AUTOSAR XML (schema 4-2-1)
standard types defined: float32, float64, sint8, sint16, sint32, uint8, uint16, uint32, boolean, dtRef_VOID, Float32, Boolean, UInt16, UInt8, UInt32
package /FoundationPkg/FoundationArchitecturePkg
  client server interface iRack
    8 x operation:
      getMaxPhysicalAssist
        arg maxPhysicalAssist: type=Nm, direction=OUT
      initialisationColumnAngle
        arg pinionAngle: type=Degrees, direction=IN
      translateColumnAngleToRackPosition
        arg pinionAngle: type=Degrees, direction=IN
        arg rackPosition: type=mm, direction=OUT
      translateColumnTorqueToRackForce
        arg columnTorque: type=Nm, direction=IN
        arg rackForce: type=kN, direction=OUT
      translateRackPositionToColumnAngle
        arg rackPosition: type=mm, direction=IN
        arg columnAngle: type=Degrees, direction=OUT
      translateRackForceToColumnTorque
        arg rackForce: type=kN, direction=IN
        arg columnTorque: type=Nm, direction=OUT
      translateColumnVelocityToRackVelocity
        arg columnVelocity: type=DegreesPerSec, direction=IN
        arg rackVelocity: type=mmPerSec, direction=OUT
      translateRackVelocityToColumnVelocity
        arg rackVelocity: type=mmPerSec, direction=IN
        arg columnVelocity: type=DegreesPerSec, direction=OUT
  constant specification iAssistTorque_AssistanceTorque_Init: value-spec={short-label=iAssistTorque_AssistanceTorque_Init, fields=[0 Nm_Unit, 0]}
  sender receiver interface iAssistTorque
    data AssistanceTorque: sw-calibration-access=READ-ONLY, type=tAssistTorque, init-value=constant-reference=iAssistTorque_AssistanceTorque_Init
  constant specification iArbitatorRequest_ActivationRequest_Init: value-spec=0
  sender receiver interface iArbitatorRequest
    data ActivationRequest: sw-calibration-access=READ-ONLY, type=tArbitrationState, init-value=constant-reference=iArbitatorRequest_ActivationRequest_Init
  constant specification iArbitorResponse_ArbitrationState_Init: value-spec=5
  sender receiver interface iArbitorResponse
    data ArbitrationState: sw-calibration-access=READ-ONLY, type=tArbitrationState, init-value=constant-reference=iArbitorResponse_ArbitrationState_Init
  constant specification iInputTorqueDemands_OverlayTorqueDemand_Init: value-spec={short-label=iInputTorqueDemands_OverlayTorqueDemand_Init, fields=[0 Nm_Unit, 0 NmPerSec_Unit, 0]}
  constant specification iInputTorqueDemands_LimitingTorqueDemand_Init: value-spec={short-label=iInputTorqueDemands_LimitingTorqueDemand_Init, fields=[0 Nm_Unit, 0]}
  sender receiver interface iInputTorqueDemands
    data OverlayTorqueDemand: sw-calibration-access=READ-ONLY, type=tInputTorque, init-value=constant-reference=iInputTorqueDemands_OverlayTorqueDemand_Init
    data LimitingTorqueDemand: sw-calibration-access=READ-ONLY, type=tAssistTorque, init-value=constant-reference=iInputTorqueDemands_LimitingTorqueDemand_Init
  constant specification iVehicleData_VehicleSpeed_Init: value-spec={short-label=iVehicleData_VehicleSpeed_Init, fields=[0 Kph_Unit, 0, 0]}
  constant specification iVehicleData_SteeringAngle_Init: value-spec={short-label=iVehicleData_SteeringAngle_Init, fields=[0 Degrees_Unit, 0]}
  sender receiver interface iVehicleData
    data VehicleSpeed: sw-calibration-access=READ-ONLY, type=tVehicleSpd, init-value=constant-reference=iVehicleData_VehicleSpeed_Init
    data SteeringAngle: sw-calibration-access=READ-ONLY, type=tColumnPosition, init-value=constant-reference=iVehicleData_SteeringAngle_Init
  5 x constant specification:
    iColumnData_ColumnTorque_Init: value-spec={short-label=iColumnData_ColumnTorque_Init, fields=[0 Nm_Unit, 0 NmPerSec_Unit, 0]}
    iColumnData_SteeringPositionLower_Init: value-spec={short-label=iColumnData_SteeringPositionLower_Init, fields=[0 Degrees_Unit, 0]}
    iColumnData_ColumnVelocity_Init: value-spec={short-label=iColumnData_ColumnVelocity_Init, fields=[0 RevsPerSec_Unit, 0 RevsPerSec_Unit, 0]}
    iColumnData_SteeringPositionUpper_Init: value-spec={short-label=iColumnData_SteeringPositionUpper_Init, fields=[0 Degrees_Unit, 0]}
    iColumnData_ColumnPositionLower_Init: value-spec={short-label=iColumnData_ColumnPositionLower_Init, fields=[0 Degrees_Unit, 0]}
  sender receiver interface iColumnData
    5 x data, all with sw-calibration-access=READ-ONLY:
      ColumnTorque: type=tInputTorque, init-value=constant-reference=iColumnData_ColumnTorque_Init
      SteeringPositionLower: type=tColumnPosition, init-value=constant-reference=iColumnData_SteeringPositionLower_Init
      ColumnVelocity: type=tColumnVelocity, init-value=constant-reference=iColumnData_ColumnVelocity_Init
      SteeringPositionUpper: type=tColumnPosition, init-value=constant-reference=iColumnData_SteeringPositionUpper_Init
      ColumnPositionLower: type=tMechanicalMotorPosition, init-value=constant-reference=iColumnData_ColumnPositionLower_Init
  constant specification iAssistCapability_Capability_Init: value-spec={short-label=iAssistCapability_Capability_Init, fields=[0 Percent_Unit, 0 Percent_Unit]}
  sender receiver interface iAssistCapability
    data Capability: sw-calibration-access=READ-ONLY, type=tAssistCapability, init-value=constant-reference=iAssistCapability_Capability_Init
package /FoundationPkg/FoundationArchitecturePkg/FoundationTypes
  unit Nm_Unit
  impl type Nm: implementation-data-type=Float32
  unit Degrees_Unit
  impl type Degrees: implementation-data-type=Float32
  unit mm_Unit
  impl type mm: implementation-data-type=Float32
  unit kN_Unit
  impl type kN: implementation-data-type=Float32
  unit DegreesPerSec_Unit
  impl type DegreesPerSec: implementation-data-type=Float32
  unit mmPerSec_Unit
  impl type mmPerSec: implementation-data-type=Float32
  compu method tQualityFactor_Compu: 0=QF_UNINITIALIZED, 0=QF_UNINITIALISED, 1=QF_UNAVAILABLE, 2=QF_DEGRADED, 3=QF_FULL
  impl type tQualityFactor: category=VALUE, base-type=sint32, compu-method=tQualityFactor_Compu
  impl type tAssistTorque: category=STRUCTURE
    element Value: implementation-data-type=Nm
    element Qf: implementation-data-type=tQualityFactor
  compu method tArbitrationState_Compu: 0=ARB_PASSIVE, 1=ARB_REQ_ACT, 2=ARB_RAMP_IN, 3=ARB_ACTIVE, 4=ARB_RAMP_OUT, 5=ARB_LOCKED, 99=ARB_READY
  impl type tArbitrationState: category=VALUE, base-type=sint32, compu-method=tArbitrationState_Compu
  unit NmPerSec_Unit
  impl type NmPerSec: implementation-data-type=Float32
  impl type tInputTorque: category=STRUCTURE
    element Value: implementation-data-type=Nm
    element Derivative: implementation-data-type=NmPerSec
    element Qf: implementation-data-type=tQualityFactor
  unit Kph_Unit
  impl type Kph: implementation-data-type=Float32
  impl type tVehicleSpd: category=STRUCTURE
    element Filtered: implementation-data-type=Kph
    element Moving: implementation-data-type=Boolean
    element Qf: implementation-data-type=tQualityFactor
  impl type tColumnPosition: category=STRUCTURE
    element Value: implementation-data-type=Degrees
    element Qf: implementation-data-type=tQualityFactor
  unit RevsPerSec_Unit
  impl type RevsPerSec: implementation-data-type=Float32
  impl type tColumnVelocity: category=STRUCTURE
    element Filtered: implementation-data-type=RevsPerSec
    element Unfiltered: implementation-data-type=RevsPerSec
    element Qf: implementation-data-type=tQualityFactor
  impl type tMechanicalMotorPosition: category=STRUCTURE
    element Value: implementation-data-type=Degrees
    element Qf: implementation-data-type=tQualityFactor
  unit Percent_Unit
  impl type Percent: implementation-data-type=Float32
  impl type tAssistCapability: category=STRUCTURE
    element Limit: implementation-data-type=Percent
    element Scale: implementation-data-type=Percent
  8 x constant specification:
    ActiveReturnTqDemand_Value_Init: value-spec=0.0
    ActiveReturnTqDemand_Qf_Init: value-spec=0
    DampingTqDemand_Value_Init: value-spec=0.0
    DampingTqDemand_Qf_Init: value-spec=0
    HvdTqDemand_Value_Init: value-spec=0.0
    HvdTqDemand_Qf_Init: value-spec=0
    ResTqDemand_Value_Init: value-spec=0.0
    ResTqDemand_Qf_Init: value-spec=0
  10 x constant specification:
    StdrTqDemand_Value_Init: value-spec=0.0
    StdrTqDemand_Qf_Init: value-spec=0
    PaTqDemand_Value_Init: value-spec=0.0
    PaTqDemand_Qf_Init: value-spec=0
    SrlTqDemand_Value_Init: value-spec=0.0
    SrlTqDemand_Qf_Init: value-spec=0
    AncTqDemand_Value_Init: value-spec=0.0
    AncTqDemand_Qf_Init: value-spec=0
    PdcTqDemand_Value_Init: value-spec=0.0
    PdcTqDemand_Qf_Init: value-spec=0
  unit Sec_Unit
  impl type Sec: implementation-data-type=Float32
  unit Hz_Unit
  impl type Hz: implementation-data-type=Float32
  unit ms_Unit
  impl type ms: implementation-data-type=UInt32
package /FoundationPkg/FoundationArchitecturePkg/FoundationTypes/ApplicationTypesPkg
  9 x app type, all with category=VALUE:
    Nm: compu {identical; unit Nm_Unit}, range phys -10..10, unit=Nm_Unit
    Float32: compu {identical}
    Degrees: compu {identical; unit Degrees_Unit}, unit=Degrees_Unit
    mm: compu {identical; unit mm_Unit}, unit=mm_Unit
    kN: compu {identical; unit kN_Unit}, unit=kN_Unit
    DegreesPerSec: compu {identical; unit DegreesPerSec_Unit}, unit=DegreesPerSec_Unit
    mmPerSec: compu {identical; unit mmPerSec_Unit}, unit=mmPerSec_Unit
    Nm_n255_0_to_255_0: compu {identical; unit Nm_Unit}, range phys -255..255, unit=Nm_Unit
    tQualityFactor: base-type=sint32, compu-method=tQualityFactor_Compu
  application record data type tAssistTorque: category=STRUCTURE
    application record element Value: category=VALUE, type=Nm_n255_0_to_255_0
    application record element Qf: category=VALUE, type=tQualityFactor
  app type tArbitrationState: category=VALUE, base-type=sint32, compu-method=tArbitrationState_Compu
  app type NmPerSec: category=VALUE, compu {identical; unit NmPerSec_Unit}, range phys -2048..2048, unit=NmPerSec_Unit  # Rate of change of torque
  application record data type tInputTorque: category=STRUCTURE
    application record element Value: category=VALUE, type=Nm
    application record element Derivative: category=VALUE, type=NmPerSec
    application record element Qf: category=VALUE, type=tQualityFactor
  app type Kph_0_to_400: category=VALUE, compu {identical; unit Kph_Unit}, range phys 0..400, unit=Kph_Unit
  app type Boolean: category=VALUE
  application record data type tVehicleSpd: category=STRUCTURE
    application record element Filtered: category=VALUE, type=Kph_0_to_400
    application record element Moving: category=VALUE, type=Boolean
    application record element Qf: category=VALUE, type=tQualityFactor
  app type Kph: category=VALUE, compu {identical; unit Kph_Unit}, unit=Kph_Unit
  app type Degrees_n720_0_to_720_0: category=VALUE, compu {identical; unit Degrees_Unit}, range phys -720..720, unit=Degrees_Unit
  application record data type tColumnPosition: category=STRUCTURE  # Measument of the Column position in degrees with range -720 - +720.
    application record element Value: category=VALUE, type=Degrees_n720_0_to_720_0
    application record element Qf: category=VALUE, type=tQualityFactor
  app type RevsPerSec: category=VALUE, compu {identical; unit RevsPerSec_Unit}, unit=RevsPerSec_Unit
  application record data type tColumnVelocity: category=STRUCTURE
    application record element Filtered: category=VALUE, type=RevsPerSec
    application record element Unfiltered: category=VALUE, type=RevsPerSec
    application record element Qf: category=VALUE, type=tQualityFactor
  app type Degrees_n29520_to_29520: category=VALUE, compu {identical; unit Degrees_Unit}, range phys -29520..29520, unit=Degrees_Unit
  application record data type tMechanicalMotorPosition: category=STRUCTURE
    application record element Value: category=VALUE, type=Degrees_n29520_to_29520
    application record element Qf: category=VALUE, type=tQualityFactor
  app type Percent: category=VALUE, compu {identical; unit Percent_Unit}, range phys 0..100, unit=Percent_Unit
  application record data type tAssistCapability: category=STRUCTURE
    application record element Limit: category=VALUE, type=Percent
    application record element Scale: category=VALUE, type=Percent
  26 x app type, all with category=VALUE:
    UInt16: compu {identical}
    Float32_0_0_to_1_0: compu {identical}, range phys 0..1
    UInt8_0_to_7: compu {identical}, range phys 0..7
    Float32_0_to_1: compu {identical}, range phys 0..1
    UInt32_0_to_3: compu {identical}, range phys 0..3
    Sec_0_1_to_1: compu {identical; unit Sec_Unit}, range phys 0.1..1, unit=Sec_Unit
    Sec_0_1_to_0_5: compu {identical; unit Sec_Unit}, range phys 0.1..0.5, unit=Sec_Unit
    Boolean_0_to_1
    Hz_10_0_to_250_0: compu {identical; unit Hz_Unit}, range phys 10..250, unit=Hz_Unit
    Kph_0_0_to_300_0: compu {identical; unit Kph_Unit}, range phys 0..300, unit=Kph_Unit
    Nm_n8_0_to_8_0: compu {identical; unit Nm_Unit}, range phys -8..8, unit=Nm_Unit
    Float32_0_0_to_200_0: compu {identical}, range phys 0..200
    NmPerSec_0_to_100: compu {identical; unit NmPerSec_Unit}, range phys 0..100, unit=NmPerSec_Unit  # Rate of change of torque
    DegreesPerSec_0_to_1000: compu {identical; unit DegreesPerSec_Unit}, range phys 0..1000, unit=DegreesPerSec_Unit
    NmPerSec_0_to_1000: compu {identical; unit NmPerSec_Unit}, range phys 0..1000, unit=NmPerSec_Unit  # Rate of change of torque
    DegreesPerSec_n500_0_to_500_0: compu {identical; unit DegreesPerSec_Unit}, range phys -500..500, unit=DegreesPerSec_Unit
    Nm_0_to_200: compu {identical; unit Nm_Unit}, range phys 0..200, unit=Nm_Unit
    Kph_0_0_to_400_0: compu {identical; unit Kph_Unit}, range phys 0..400, unit=Kph_Unit
    Nm_0_0_to_20_0: compu {identical; unit Nm_Unit}, range phys 0..20, unit=Nm_Unit
    Nm_0_0_to_60_0: compu {identical; unit Nm_Unit}, range phys 0..60, unit=Nm_Unit
    ms_0_to_500: compu {identical; unit ms_Unit}, range phys 0..500, unit=ms_Unit
    UInt32: compu {identical}
    Nm_0_0_to_10_0: compu {identical; unit Nm_Unit}, range phys 0..10, unit=Nm_Unit
    Percent_0_0_to_100_0: compu {identical; unit Percent_Unit}, range phys 0..100, unit=Percent_Unit
    Nm_0_0_to_200_0: compu {identical; unit Nm_Unit}, range phys 0..200, unit=Nm_Unit
    NmPerSec_0_1_to_20_0: compu {identical; unit NmPerSec_Unit}, range phys 0.1..20, unit=NmPerSec_Unit  # Rate of change of torque
package /DataTypeMappingSets
  data type mapping set MappingSet
    data-type-maps:
      application-data-type=Float32, implementation-data-type=Float32
      application-data-type=Nm, implementation-data-type=Nm
      application-data-type=Degrees, implementation-data-type=Degrees
      application-data-type=mm, implementation-data-type=mm
      application-data-type=kN, implementation-data-type=kN
      application-data-type=DegreesPerSec, implementation-data-type=DegreesPerSec
      application-data-type=mmPerSec, implementation-data-type=mmPerSec
      application-data-type=Nm_n255_0_to_255_0, implementation-data-type=Nm
      application-data-type=tQualityFactor, implementation-data-type=tQualityFactor
      application-data-type=tAssistTorque, implementation-data-type=tAssistTorque
      application-data-type=tArbitrationState, implementation-data-type=tArbitrationState
      application-data-type=NmPerSec, implementation-data-type=NmPerSec
      application-data-type=tInputTorque, implementation-data-type=tInputTorque
      application-data-type=Kph_0_to_400, implementation-data-type=Kph
      application-data-type=Boolean, implementation-data-type=Boolean
      application-data-type=Kph, implementation-data-type=Kph
      application-data-type=tVehicleSpd, implementation-data-type=tVehicleSpd
      application-data-type=Degrees_n720_0_to_720_0, implementation-data-type=Degrees
      application-data-type=tColumnPosition, implementation-data-type=tColumnPosition
      application-data-type=RevsPerSec, implementation-data-type=RevsPerSec
      application-data-type=tColumnVelocity, implementation-data-type=tColumnVelocity
      application-data-type=Degrees_n29520_to_29520, implementation-data-type=Degrees
      application-data-type=tMechanicalMotorPosition, implementation-data-type=tMechanicalMotorPosition
      application-data-type=tSystemStates, implementation-data-type=tSystemStates
      application-data-type=Percent, implementation-data-type=Percent
      application-data-type=tAssistCapability, implementation-data-type=tAssistCapability
      application-data-type=UInt16, implementation-data-type=UInt16
      application-data-type=Float32_0_0_to_1_0, implementation-data-type=Float32
      application-data-type=UInt8_0_to_7, implementation-data-type=UInt8
      application-data-type=Float32_0_to_1, implementation-data-type=Float32
      application-data-type=UInt32_0_to_3, implementation-data-type=UInt32
      application-data-type=Sec_0_1_to_1, implementation-data-type=Sec
      application-data-type=Sec_0_1_to_0_5, implementation-data-type=Sec
      application-data-type=Boolean_0_to_1, implementation-data-type=Boolean
      application-data-type=Hz_10_0_to_250_0, implementation-data-type=Hz
      application-data-type=Kph_0_0_to_300_0, implementation-data-type=Kph
      application-data-type=tSrlVspdBkpts_0_0_to_300_0, implementation-data-type=tSrlVspdBkpts
      application-data-type=Nm_n8_0_to_8_0, implementation-data-type=Nm
      application-data-type=tSrlTqBkpts_n8_0_to_8_0, implementation-data-type=tSrlTqBkpts
      application-data-type=Float32_0_0_to_200_0, implementation-data-type=Float32
      application-data-type=NmPerSec_0_to_100, implementation-data-type=NmPerSec
      application-data-type=DegreesPerSec_0_to_1000, implementation-data-type=DegreesPerSec
      application-data-type=tSrlVBkpts_0_to_1000, implementation-data-type=tSrlVBkpts
      application-data-type=NmPerSec_0_to_1000, implementation-data-type=NmPerSec
      application-data-type=tSrlTqSlewRateMap_0_to_1000, implementation-data-type=tSrlTqSlewRateMap
      application-data-type=DegreesPerSec_n500_0_to_500_0, implementation-data-type=DegreesPerSec
      application-data-type=tSrlMap1D_n500_0_to_500_0, implementation-data-type=tSrlMap1D
      application-data-type=tSrlMap1D, implementation-data-type=tSrlMap1D
      application-data-type=tSrlMap2D_n500_0_to_500_0, implementation-data-type=tSrlMap2D
      application-data-type=Nm_0_to_200, implementation-data-type=Nm
      application-data-type=tArbRuleBase, implementation-data-type=tArbRuleBase
      application-data-type=Kph_0_0_to_400_0, implementation-data-type=Kph
      application-data-type=Nm_0_0_to_20_0, implementation-data-type=Nm
      application-data-type=Nm_0_0_to_60_0, implementation-data-type=Nm
      application-data-type=UInt32, implementation-data-type=UInt32
      application-data-type=ms_0_to_500, implementation-data-type=ms
      application-data-type=Nm_0_0_to_10_0, implementation-data-type=Nm
      application-data-type=Percent_0_0_to_100_0, implementation-data-type=Percent
      application-data-type=Nm_0_0_to_200_0, implementation-data-type=Nm
      application-data-type=NmPerSec_0_1_to_20_0, implementation-data-type=NmPerSec
package /SwAddrMethods
  7 x sw addr method, all with memory-allocation-keyword-policy=ADDR-METHOD-SHORT-NAME, section-type=CALIBRATION-ONLINE:
    VehicleTune
    PlatformTune
    DevelopmentTune
    SteeringTune
    SensorTune
    EppTune
    GearTune
package /FordPkg/FordArchitecturePkg
  constant specification iSystemStates_SystemState_Init: value-spec=0
  sender receiver interface iSystemStates
    data SystemState: sw-calibration-access=READ-ONLY, type=tSystemStates, init-value=constant-reference=iSystemStates_SystemState_Init
package /FordPkg/FordArchitecturePkg/FordBx726ArchitecturePkg
  constant specification iRcpTorqueDmd_Hfm2PntqCmd_Init: value-spec={short-label=iRcpTorqueDmd_Hfm2PntqCmd_Init, fields=[0 Nm_Unit, 0]}
  constant specification iRcpTorqueDmd_LflPntqCmd_Init: value-spec={short-label=iRcpTorqueDmd_LflPntqCmd_Init, fields=[0 Nm_Unit, 0]}
  constant specification iRcpTorqueDmd_SrlPntqCmd_Init: value-spec={short-label=iRcpTorqueDmd_SrlPntqCmd_Init, fields=[0 Nm_Unit, 0]}
  sender receiver interface iRcpTorqueDmd
    data Hfm2PntqCmd: sw-calibration-access=READ-ONLY, type=tAssistTorque, init-value=constant-reference=iRcpTorqueDmd_Hfm2PntqCmd_Init
    data LflPntqCmd: sw-calibration-access=READ-ONLY, type=tAssistTorque, init-value=constant-reference=iRcpTorqueDmd_LflPntqCmd_Init
    data SrlPntqCmd: sw-calibration-access=READ-ONLY, type=tAssistTorque, init-value=constant-reference=iRcpTorqueDmd_SrlPntqCmd_Init
  constant specification iFihFnSts_AncExecStopped_Init: value-spec=0
  constant specification iFihFnSts_PdcExecStopped_Init: value-spec=0
  constant specification iFihFnSts_StdrExecStopped_Init: value-spec=0
  sender receiver interface iFihFnSts
    data AncExecStopped: sw-calibration-access=READ-ONLY, type=Boolean, init-value=constant-reference=iFihFnSts_AncExecStopped_Init
    data PdcExecStopped: sw-calibration-access=READ-ONLY, type=Boolean, init-value=constant-reference=iFihFnSts_PdcExecStopped_Init
    data StdrExecStopped: sw-calibration-access=READ-ONLY, type=UInt16, init-value=constant-reference=iFihFnSts_StdrExecStopped_Init
  constant specification iArbGain_PaBldGain_Init: value-spec=0
  sender receiver interface iArbGain
    data PaBldGain: sw-calibration-access=READ-ONLY, type=Float32_0_0_to_1_0, init-value=constant-reference=iArbGain_PaBldGain_Init
package /FordPkg/FordArchitecturePkg/FordBx726ArchitecturePkg/FordBx726EpsControllerPkg
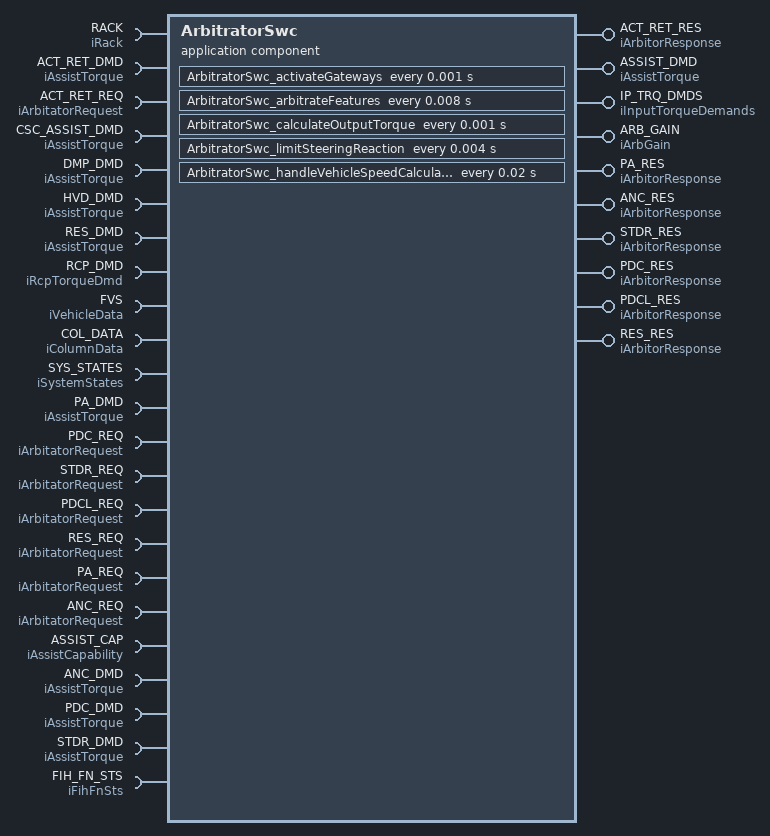
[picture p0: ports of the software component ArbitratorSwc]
  application sw component type ArbitratorSwc
    require port RACK: required-interface=iRack
    require port ACT_RET_DMD: nonqueued-receiver-com-spec{data-element=AssistanceTorque, init-value=constant-reference=iAssistTorque_AssistanceTorque_Init}, required-interface=iAssistTorque
    require port ACT_RET_REQ: nonqueued-receiver-com-spec{data-element=ActivationRequest, init-value=constant-reference=iArbitatorRequest_ActivationRequest_Init}, required-interface=iArbitatorRequest
    provide port ACT_RET_RES: nonqueued-sender-com-spec{data-element=ArbitrationState, init-value=constant-reference=iArbitorResponse_ArbitrationState_Init}, provided-interface=iArbitorResponse
    provide port ASSIST_DMD: nonqueued-sender-com-spec{data-element=AssistanceTorque, init-value=constant-reference=iAssistTorque_AssistanceTorque_Init}, provided-interface=iAssistTorque
    require port CSC_ASSIST_DMD: nonqueued-receiver-com-spec{data-element=AssistanceTorque, init-value=constant-reference=iAssistTorque_AssistanceTorque_Init}, required-interface=iAssistTorque
    require port DMP_DMD: nonqueued-receiver-com-spec{data-element=AssistanceTorque, init-value=constant-reference=iAssistTorque_AssistanceTorque_Init}, required-interface=iAssistTorque
    require port HVD_DMD: nonqueued-receiver-com-spec{data-element=AssistanceTorque, init-value=constant-reference=iAssistTorque_AssistanceTorque_Init}, required-interface=iAssistTorque
    provide port IP_TRQ_DMDS: provided-interface=iInputTorqueDemands
      provided-com-specs:
        data-element=OverlayTorqueDemand, init-value=constant-reference=iInputTorqueDemands_OverlayTorqueDemand_Init
        data-element=LimitingTorqueDemand, init-value=constant-reference=iInputTorqueDemands_LimitingTorqueDemand_Init
    17 x require port:
      RES_DMD: nonqueued-receiver-com-spec{data-element=AssistanceTorque, init-value=constant-reference=iAssistTorque_AssistanceTorque_Init}, required-interface=iAssistTorque
      RCP_DMD: required-interface=iRcpTorqueDmd
        required-com-specs:
          data-element=Hfm2PntqCmd, init-value=constant-reference=iRcpTorqueDmd_Hfm2PntqCmd_Init
          data-element=LflPntqCmd, init-value=constant-reference=iRcpTorqueDmd_LflPntqCmd_Init
          data-element=SrlPntqCmd, init-value=constant-reference=iRcpTorqueDmd_SrlPntqCmd_Init
      FVS: required-interface=iVehicleData
        required-com-specs:
          data-element=VehicleSpeed, init-value=constant-reference=iVehicleData_VehicleSpeed_Init
          data-element=SteeringAngle, init-value=constant-reference=iVehicleData_SteeringAngle_Init
      COL_DATA: required-interface=iColumnData
        required-com-specs:
          data-element=ColumnTorque, init-value=constant-reference=iColumnData_ColumnTorque_Init
          data-element=SteeringPositionLower, init-value=constant-reference=iColumnData_SteeringPositionLower_Init
          data-element=ColumnVelocity, init-value=constant-reference=iColumnData_ColumnVelocity_Init
          data-element=SteeringPositionUpper, init-value=constant-reference=iColumnData_SteeringPositionUpper_Init
          data-element=ColumnPositionLower, init-value=constant-reference=iColumnData_ColumnPositionLower_Init
      SYS_STATES: nonqueued-receiver-com-spec{data-element=SystemState, init-value=constant-reference=iSystemStates_SystemState_Init}, required-interface=iSystemStates
      PA_DMD: nonqueued-receiver-com-spec{data-element=AssistanceTorque, init-value=constant-reference=iAssistTorque_AssistanceTorque_Init}, required-interface=iAssistTorque
      PDC_REQ: nonqueued-receiver-com-spec{data-element=ActivationRequest, init-value=constant-reference=iArbitatorRequest_ActivationRequest_Init}, required-interface=iArbitatorRequest
      STDR_REQ: nonqueued-receiver-com-spec{data-element=ActivationRequest, init-value=constant-reference=iArbitatorRequest_ActivationRequest_Init}, required-interface=iArbitatorRequest
      PDCL_REQ: nonqueued-receiver-com-spec{data-element=ActivationRequest, init-value=constant-reference=iArbitatorRequest_ActivationRequest_Init}, required-interface=iArbitatorRequest
      RES_REQ: nonqueued-receiver-com-spec{data-element=ActivationRequest, init-value=constant-reference=iArbitatorRequest_ActivationRequest_Init}, required-interface=iArbitatorRequest
      PA_REQ: nonqueued-receiver-com-spec{data-element=ActivationRequest, init-value=constant-reference=iArbitatorRequest_ActivationRequest_Init}, required-interface=iArbitatorRequest
      ANC_REQ: nonqueued-receiver-com-spec{data-element=ActivationRequest, init-value=constant-reference=iArbitatorRequest_ActivationRequest_Init}, required-interface=iArbitatorRequest
      ASSIST_CAP: nonqueued-receiver-com-spec{data-element=Capability, init-value=constant-reference=iAssistCapability_Capability_Init}, required-interface=iAssistCapability
      ANC_DMD: nonqueued-receiver-com-spec{data-element=AssistanceTorque, init-value=constant-reference=iAssistTorque_AssistanceTorque_Init}, required-interface=iAssistTorque
      PDC_DMD: nonqueued-receiver-com-spec{data-element=AssistanceTorque, init-value=constant-reference=iAssistTorque_AssistanceTorque_Init}, required-interface=iAssistTorque
      STDR_DMD: nonqueued-receiver-com-spec{data-element=AssistanceTorque, init-value=constant-reference=iAssistTorque_AssistanceTorque_Init}, required-interface=iAssistTorque
      FIH_FN_STS: required-interface=iFihFnSts
        required-com-specs:
          data-element=AncExecStopped, init-value=constant-reference=iFihFnSts_AncExecStopped_Init
          data-element=PdcExecStopped, init-value=constant-reference=iFihFnSts_PdcExecStopped_Init
          data-element=StdrExecStopped, init-value=constant-reference=iFihFnSts_StdrExecStopped_Init
    7 x provide port:
      ARB_GAIN: nonqueued-sender-com-spec{data-element=PaBldGain, init-value=constant-reference=iArbGain_PaBldGain_Init}, provided-interface=iArbGain
      PA_RES: nonqueued-sender-com-spec{data-element=ArbitrationState, init-value=constant-reference=iArbitorResponse_ArbitrationState_Init}, provided-interface=iArbitorResponse
      ANC_RES: nonqueued-sender-com-spec{data-element=ArbitrationState, init-value=constant-reference=iArbitorResponse_ArbitrationState_Init}, provided-interface=iArbitorResponse
      STDR_RES: nonqueued-sender-com-spec{data-element=ArbitrationState, init-value=constant-reference=iArbitorResponse_ArbitrationState_Init}, provided-interface=iArbitorResponse
      PDC_RES: nonqueued-sender-com-spec{data-element=ArbitrationState, init-value=constant-reference=iArbitorResponse_ArbitrationState_Init}, provided-interface=iArbitorResponse
      PDCL_RES: nonqueued-sender-com-spec{data-element=ArbitrationState, init-value=constant-reference=iArbitorResponse_ArbitrationState_Init}, provided-interface=iArbitorResponse
      RES_RES: nonqueued-sender-com-spec{data-element=ArbitrationState, init-value=constant-reference=iArbitorResponse_ArbitrationState_Init}, provided-interface=iArbitorResponse
    behavior ArbitratorSwc_IB: data-type-mapping=MappingSet, handle-termination-and-restart=NO-SUPPORT
      timing event Event_activateGateways: start-on-event=ArbitratorSwc_activateGateways, period=0.001
      timing event Event_arbitrateFeatures: start-on-event=ArbitratorSwc_arbitrateFeatures, period=0.008
      timing event Event_calculateOutputTorque: start-on-event=ArbitratorSwc_calculateOutputTorque, period=0.001
      init event Event_initialiser_Init: start-on-event=ArbitratorSwc_initialiser
      timing event Event_limitSteeringReaction: start-on-event=ArbitratorSwc_limitSteeringReaction, period=0.004
      timing event Event_handleVehicleSpeedCalculations: start-on-event=ArbitratorSwc_handleVehicleSpeedCalculations, period=0.02
      implicit-inter-runnable-variables:
        26 x data, all with sw-calibration-access=READ-ONLY:
          ActiveReturnState: type=tArbitrationState, init-value=constant-reference=ArbitratorSwc_ActiveReturnState_Init
          ActiveReturnTqDemand_Value: type=Nm, init-value=constant-reference=ActiveReturnTqDemand_Value_Init
          ActiveReturnTqDemand_Qf: type=tQualityFactor, init-value=constant-reference=ActiveReturnTqDemand_Qf_Init
          DampingTqDemand_Value: type=Nm, init-value=constant-reference=DampingTqDemand_Value_Init
          DampingTqDemand_Qf: type=tQualityFactor, init-value=constant-reference=DampingTqDemand_Qf_Init
          HvdTqDemand_Value: type=Nm, init-value=constant-reference=HvdTqDemand_Value_Init
          HvdTqDemand_Qf: type=tQualityFactor, init-value=constant-reference=HvdTqDemand_Qf_Init
          ResTqDemand_Value: type=Nm, init-value=constant-reference=ResTqDemand_Value_Init
          ResTqDemand_Qf: type=tQualityFactor, init-value=constant-reference=ResTqDemand_Qf_Init
          SrlSpdIndex: type=UInt8, init-value=constant-reference=ArbitratorSwc_SrlSpdIndex_Init
          SrlSpdFraction: type=Float32, init-value=constant-reference=ArbitratorSwc_SrlSpdFraction_Init
          StdrTqDemand_Value: type=Nm, init-value=constant-reference=StdrTqDemand_Value_Init
          StdrTqDemand_Qf: type=tQualityFactor, init-value=constant-reference=StdrTqDemand_Qf_Init
          PaTqDemand_Value: type=Nm, init-value=constant-reference=PaTqDemand_Value_Init
          PaTqDemand_Qf: type=tQualityFactor, init-value=constant-reference=PaTqDemand_Qf_Init
          SrlTqDemand_Value: type=Nm, init-value=constant-reference=SrlTqDemand_Value_Init
          SrlTqDemand_Qf: type=tQualityFactor, init-value=constant-reference=SrlTqDemand_Qf_Init
          PdcState: type=tArbitrationState, init-value=constant-reference=ArbitratorSwc_PdcState_Init
          StdrState: type=tArbitrationState, init-value=constant-reference=ArbitratorSwc_StdrState_Init
          AncState: type=tArbitrationState, init-value=constant-reference=ArbitratorSwc_AncState_Init
          PaState: type=tArbitrationState, init-value=constant-reference=ArbitratorSwc_PaState_Init
          AncTqDemand_Value: type=Nm, init-value=constant-reference=AncTqDemand_Value_Init
          AncTqDemand_Qf: type=tQualityFactor, init-value=constant-reference=AncTqDemand_Qf_Init
          PdcTqDemand_Value: type=Nm, init-value=constant-reference=PdcTqDemand_Value_Init
          PdcTqDemand_Qf: type=tQualityFactor, init-value=constant-reference=PdcTqDemand_Qf_Init
          AncDiagStatus: type=UInt32, init-value=constant-reference=ArbitratorSwc_AncDiagStatus_Init
      per-instance-parameters:
        28 x parameter data prototype, all with sw-calibration-access=READ-WRITE:
          ARB_PA_MODE_IN_TIME: category=VALUE, sw-addr-method=VehicleTune, type=Sec_0_1_to_1, init-value=constant-reference=VehicleTune_ARB_PA_MODE_IN_TIME_Init
          ARB_PA_MODE_OUT_TIME: category=VALUE, sw-addr-method=VehicleTune, type=Sec_0_1_to_0_5, init-value=constant-reference=VehicleTune_ARB_PA_MODE_OUT_TIME_Init
          ARB_SWITCH_SWS_FILT: category=VALUE, sw-addr-method=PlatformTune, type=Boolean_0_to_1, init-value=constant-reference=PlatformTune_ARB_SWITCH_SWS_FILT_Init
          ARB_SWS_LP_FREQ: category=VALUE, sw-addr-method=PlatformTune, type=Hz_10_0_to_250_0, init-value=constant-reference=PlatformTune_ARB_SWS_LP_FREQ_Init
          ARB_LIMIT_VX_IN: category=ARRAY, sw-addr-method=PlatformTune, type=tSrlVspdBkpts_0_0_to_300_0, init-value=constant-reference=PlatformTune_ARB_LIMIT_VX_IN_Init
          ARB_LIMIT_SWT_IN: category=ARRAY, sw-addr-method=PlatformTune, type=tSrlTqBkpts_n8_0_to_8_0, init-value=constant-reference=PlatformTune_ARB_LIMIT_SWT_IN_Init
          ARB_AMPLITUDE_LIMIT_TQ_OUT: category=VALUE, sw-addr-method=PlatformTune, type=Float32_0_0_to_200_0, init-value=constant-reference=PlatformTune_ARB_AMPLITUDE_LIMIT_TQ_OUT_Init
          ARB_AMPLITUDE_FRACTION_OVERRUN: category=VALUE, sw-addr-method=PlatformTune, type=Float32_0_to_1, init-value=constant-reference=PlatformTune_ARB_AMPLITUDE_FRACTION_OVERRUN_Init
          ARB_FIXED_OVERRUN_RAMP_RATE: category=VALUE, sw-addr-method=PlatformTune, type=NmPerSec_0_to_100, init-value=constant-reference=PlatformTune_ARB_FIXED_OVERRUN_RAMP_RATE_Init
          ARB_OVERRUN_RAMP_RATE_SWS_ERROR_IN: category=ARRAY, sw-addr-method=PlatformTune, type=tSrlVBkpts_0_to_1000, init-value=constant-reference=PlatformTune_ARB_OVERRUN_RAMP_RATE_SWS_ERROR_IN_Init
          ARB_OVERRUN_RAMP_RATE_OUT: category=ARRAY, sw-addr-method=PlatformTune, type=tSrlTqSlewRateMap_0_to_1000, init-value=constant-reference=PlatformTune_ARB_OVERRUN_RAMP_RATE_OUT_Init
          ARB_AMPLITUDE_FRACTION_RECOVERY: category=VALUE, sw-addr-method=PlatformTune, type=Float32_0_to_1, init-value=constant-reference=PlatformTune_ARB_AMPLITUDE_FRACTION_RECOVERY_Init
          ARB_RECOVERY_RAMP_RATE_STAGE1: category=VALUE, sw-addr-method=PlatformTune, type=NmPerSec_0_to_100, init-value=constant-reference=PlatformTune_ARB_RECOVERY_RAMP_RATE_STAGE1_Init
          ARB_RECOVERY_RAMP_RATE_STAGE2: category=VALUE, sw-addr-method=PlatformTune, type=NmPerSec_0_to_100, init-value=constant-reference=PlatformTune_ARB_RECOVERY_RAMP_RATE_STAGE2_Init
          ARB_LIMIT_SWS_OUT: category=ARRAY, sw-addr-method=PlatformTune, type=tSrlMap2D_n500_0_to_500_0, init-value=constant-reference=PlatformTune_ARB_LIMIT_SWS_OUT_Init
          ARB_LIM_HYS: category=VALUE, sw-addr-method=PlatformTune, type=Float32_0_to_1, init-value=constant-reference=PlatformTune_ARB_LIM_HYS_Init
          ARB_LOWER_AMPLITUDE_LIMIT: category=VALUE, sw-addr-method=PlatformTune, type=Nm_0_to_200, init-value=constant-reference=PlatformTune_ARB_LOWER_AMPLITUDE_LIMIT_Init
          ARB_AMPLITUDE_LIMIT_VX_IN: category=ARRAY, sw-addr-method=PlatformTune, type=tSrlVspdBkpts_0_0_to_300_0, init-value=constant-reference=PlatformTune_ARB_AMPLITUDE_LIMIT_VX_IN_Init
          ARB_RULEBASE: category=RECORD, sw-addr-method=PlatformTune, type=tArbRuleBase, init-value=constant-reference=PlatformTune_ARB_RULEBASE_Init  # Default value 0, /*VERSION*/ TRUE, /*ARB_ANC_ALLOW_ACTIVATE_RULE_PDC */ TRUE, /*ARB_ANC_ALLOW_ACTIVATE_RULE_PDCL */ TRUE, /*ARB_ANC_ALLOW_ACTIVATE_RULE_STDR */ TRUE, /*ARB_ANC_ALLOW_ACTIVATE_RULE_RES */ TRUE, /*ARB_ANC_ALLOW_ACTIVATE_RULE_PA */ TRUE, /*ARB_PDC_ALLOW_ACTIVATE_RULE_ANC */ TRUE, /*ARB_PDC_ALLOW_ACTIVATE_RULE_PDCL */ TRUE, /*ARB_PDC_ALLOW_ACTIVATE_RULE_STDR */ TRUE, /*ARB_PDC_ALLOW_ACTIVATE_RULE_RES */ TRUE, /*ARB_PDC_ALLOW_ACTIVATE_RULE_PA */ TRUE, /*ARB_PDCL_ALLOW_ACTIVATE_RULE_ANC */ TRUE, /*ARB_PDCL_ALLOW_ACTIVATE_RULE_PDC */ TRUE, /*ARB_PDCL_ALLOW_ACTIVATE_RULE_STDR */ TRUE, /*ARB_PDCL_ALLOW_ACTIVATE_RULE_RES */ TRUE, /*ARB_PDCL_ALLOW_ACTIVATE_RULE_PA */ TRUE, /*ARB_STDR_ALLOW_ACTIVATE_RULE_ANC */ TRUE, /*ARB_STDR_ALLOW_ACTIVATE_RULE_PDC */ TRUE, /*ARB_STDR_ALLOW_ACTIVATE_RULE_PDCL */ TRUE, /*ARB_STDR_ALLOW_ACTIVATE_RULE_RES */ TRUE, /*ARB_STDR_ALLOW_ACTIVATE_RULE_PA */ TRUE, /*ARB_RES_ALLOW_ACTIVATE_RULE_ANC */ TRUE, /*ARB_RES_ALLOW_ACTIVATE_RULE_PDC */ TRUE, /*ARB_RES_ALLOW_ACTIVATE_RULE_PDCL */ TRUE, /*ARB_RES_ALLOW_ACTIVATE_RULE_STDR */ TRUE, /*ARB_RES_ALLOW_ACTIVATE_RULE_PA */ TRUE, /*ARB_PA_ALLOW_ACTIVATE_RULE_ANC */ TRUE, /*ARB_PA_ALLOW_ACTIVATE_RULE_PDC */ TRUE, /*ARB_PA_ALLOW_ACTIVATE_RULE_PDCL */ TRUE, /*ARB_PA_ALLOW_ACTIVATE_RULE_STDR */ TRUE, /*ARB_PA_ALLOW_ACTIVATE_RULE_RES */ TRUE, /*ARB_ANC_CONTIN_IF_ACTIVE_RULE_PDC */ TRUE, /*ARB_ANC_CONTIN_IF_ACTIVE_RULE_PDCL */ TRUE, /*ARB_ANC_CONTIN_IF_ACTIVE_RULE_STDR */ TRUE, /*ARB_ANC_CONTIN_IF_ACTIVE_RULEE_RES */ TRUE, /*ARB_ANC_CONTIN_IF_ACTIVE_RULE_PA */ TRUE, /*ARB_PDC_CONTIN_IF_ACTIVE_RULE_ANC */ TRUE, /*ARB_PDC_CONTIN_IF_ACTIVE_RULE_PDCL */ TRUE, /*ARB_PDC_CONTIN_IF_ACTIVE_RULE_STDR */ TRUE, /*ARB_PDC_CONTIN_IF_ACTIVE_RULE_RES */ TRUE, /*ARB_PDC_CONTIN_IF_ACTIVE_RULE_EAC */ TRUE, /*ARB_PDCL_CONTIN_IF_ACTIVE_RULE_ANC */ TRUE, /*ARB_PDCL_CONTIN_IF_ACTIVE_RULE_PDC */ TRUE, /*ARB_PDCL_CONTIN_IF_ACTIVE_RULE_STDR */ TRUE, /*ARB_PDCL_CONTIN_IF_ACTIVE_RULE_RES */ TRUE, /*ARB_PDCL_CONTIN_IF_ACTIVE_RULE_PA */ TRUE, /*ARB_STDR_CONTIN_IF_ACTIVE_RULE_ANC */ TRUE, /*ARB_STDR_CONTIN_IF_ACTIVE_RULE_PDC */ TRUE, /*ARB_STDR_CONTIN_IF_ACTIVE_RULE_PDCL */ TRUE, /*ARB_STDR_CONTIN_IF_ACTIVE_RULE_RES */ TRUE, /*ARB_STDR_CONTIN_IF_ACTIVE_RULE_PA */ TRUE, /*ARB_RES_CONTIN_IF_ACTIVE_RULE_ANC */ TRUE, /*ARB_RES_CONTIN_IF_ACTIVE_RULE_PDC */ TRUE, /*ARB_RES_CONTIN_IF_ACTIVE_RULE_PDCL */ TRUE, /*ARB_RES_CONTIN_IF_ACTIVE_RULE_STDR */ TRUE, /*ARB_RES_CONTIN_IF_ACTIVE_RULE_PA */ TRUE, /*ARB_PA_CONTIN_IF_ACTIVE_RULE_ANC */ TRUE, /*ARB_PA_CONTIN_IF_ACTIVE_RULE_PDC */ TRUE, /*ARB_PA_CONTIN_IF_ACTIVE_RULE_PDCL */ TRUE, /*ARB_PA_CONTIN_IF_ACTIVE_RULE_STDR */ TRUE, /*ARB_PA_CONTIN_IF_ACTIVE_RULE_RES */ FALSE, /*ARB_ANC_IF_LIMITED_ASSIST */ FALSE, /*ARB_PDC_IF_LIMITED_ASSIST */ FALSE, /*ARB_PDCL_IF_LIMITED_ASSIST */ FALSE, /*ARB_STDR_IF_LIMITED_ASSIST */ FALSE, /*ARB_RES_IF_LIMITED_ASSIST */ FALSE /*ARB_PA_IF_LIMITED_ASSIST */
          ARB_DEFAULT_SPEED: category=VALUE, sw-addr-method=PlatformTune, type=Kph_0_0_to_400_0, init-value=constant-reference=PlatformTune_ARB_DEFAULT_SPEED_Init
          ARB_MONITOR_ANC_ZERO_BAND_TORQUE: category=VALUE, sw-addr-method=PlatformTune, type=Nm_0_0_to_20_0, init-value=constant-reference=PlatformTune_ARB_MONITOR_ANC_ZERO_BAND_TORQUE_Init
          ARB_MONITOR_ANC_MAX_MOTOR_TORQUE: category=VALUE, sw-addr-method=PlatformTune, type=Nm_0_0_to_60_0, init-value=constant-reference=PlatformTune_ARB_MONITOR_ANC_MAX_MOTOR_TORQUE_Init
          ARB_MONITOR_ANC_LOW_FREQ_TIME_TH: category=VALUE, sw-addr-method=PlatformTune, type=ms_0_to_500, init-value=constant-reference=PlatformTune_ARB_MONITOR_ANC_LOW_FREQ_TIME_TH_Init
          ARB_MONITOR_ANC_TORQUE_TREND_ALPHA: category=VALUE, sw-addr-method=PlatformTune, type=Float32_0_0_to_1_0, init-value=constant-reference=PlatformTune_ARB_MONITOR_ANC_TORQUE_TREND_ALPHA_Init
          ARB_MONITOR_ANC_DC_TREND_TORQUE_TH: category=VALUE, sw-addr-method=PlatformTune, type=Nm_0_0_to_10_0, init-value=constant-reference=PlatformTune_ARB_MONITOR_ANC_DC_TREND_TORQUE_TH_Init
          ARB_NORMAL_ASSIST_TQ_LEVEL: category=VALUE, sw-addr-method=PlatformTune, type=Percent_0_0_to_100_0, init-value=constant-reference=PlatformTune_ARB_NORMAL_ASSIST_TQ_LEVEL_Init
          ARB_LIMITER_PDC_MAX_TQ: category=VALUE, sw-addr-method=PlatformTune, type=Nm_0_0_to_200_0, init-value=constant-reference=PlatformTune_ARB_LIMITER_PDC_MAX_TQ_Init
          ARB_LIMITER_PDC_STQR: category=VALUE, sw-addr-method=PlatformTune, type=NmPerSec_0_1_to_20_0, init-value=constant-reference=PlatformTune_ARB_LIMITER_PDC_STQR_Init
      6 x runnable:
        ArbitratorSwc_activateGateways: symbol=Arbitrator_activateGateways  # Calculate the input torque, both overlay and limiting, for feeding into the assist function. The arbitrator is responsible for determining which of the input torque demands shall be feed into the overlay and limiting torque demands. Overlay Torque Demand represents torque demands input prior to the assist function as if they are 'over-layed' on top of the driver torque input measured on the steering column. Limiting Torque Demand represents torque demands that 'limit' the assist demand produced by the assist function.
          data-read-access:
            11 x access:
              R_ACT_RET_DMD_AssistanceTorque: accessed-variable=ACT_RET_DMD.AssistanceTorque
              R_DMP_DMD_AssistanceTorque: accessed-variable=DMP_DMD.AssistanceTorque
              R_HVD_DMD_AssistanceTorque: accessed-variable=HVD_DMD.AssistanceTorque
              R_RES_DMD_AssistanceTorque: accessed-variable=RES_DMD.AssistanceTorque
              R_RCP_DMD_Hfm2PntqCmd: accessed-variable=RCP_DMD.Hfm2PntqCmd
              R_RCP_DMD_LflPntqCmd: accessed-variable=RCP_DMD.LflPntqCmd
              R_RCP_DMD_SrlPntqCmd: accessed-variable=RCP_DMD.SrlPntqCmd
              R_STDR_DMD_AssistanceTorque: accessed-variable=STDR_DMD.AssistanceTorque
              R_PDC_DMD_AssistanceTorque: accessed-variable=PDC_DMD.AssistanceTorque
              R_ANC_DMD_AssistanceTorque: accessed-variable=ANC_DMD.AssistanceTorque
              R_PA_DMD_AssistanceTorque: accessed-variable=PA_DMD.AssistanceTorque
          data-write-access:
            access W_IP_TRQ_DMDS_OverlayTorqueDemand: accessed-variable=IP_TRQ_DMDS.OverlayTorqueDemand
          7 x parameter access:
            ARB_LIMITER_PDC_MAX_TQ: accessed-parameter=ARB_LIMITER_PDC_MAX_TQ
            ARB_LIMITER_PDC_STQR: accessed-parameter=ARB_LIMITER_PDC_STQR
            ARB_MONITOR_ANC_DC_TREND_TORQUE_TH: accessed-parameter=ARB_MONITOR_ANC_DC_TREND_TORQUE_TH
            ARB_MONITOR_ANC_LOW_FREQ_TIME_TH: accessed-parameter=ARB_MONITOR_ANC_LOW_FREQ_TIME_TH
            ARB_MONITOR_ANC_MAX_MOTOR_TORQUE: accessed-parameter=ARB_MONITOR_ANC_MAX_MOTOR_TORQUE
            ARB_MONITOR_ANC_TORQUE_TREND_ALPHA: accessed-parameter=ARB_MONITOR_ANC_TORQUE_TREND_ALPHA
            ARB_MONITOR_ANC_ZERO_BAND_TORQUE: accessed-parameter=ARB_MONITOR_ANC_ZERO_BAND_TORQUE
          read-local-variables:
            5 x access:
              RV_ActiveReturnState: accessed-variable=ActiveReturnState
              RV_PdcState: accessed-variable=PdcState
              RV_AncState: accessed-variable=AncState
              RV_StdrState: accessed-variable=StdrState
              RV_PaState: accessed-variable=PaState
          written-local-variables:
            17 x access:
              WV_ActiveReturnTqDemand_Value: accessed-variable=ActiveReturnTqDemand_Value
              WV_ActiveReturnTqDemand_Qf: accessed-variable=ActiveReturnTqDemand_Qf
              WV_DampingTqDemand_Value: accessed-variable=DampingTqDemand_Value
              WV_DampingTqDemand_Qf: accessed-variable=DampingTqDemand_Qf
              WV_HvdTqDemand_Value: accessed-variable=HvdTqDemand_Value
              WV_HvdTqDemand_Qf: accessed-variable=HvdTqDemand_Qf
              WV_ResTqDemand_Value: accessed-variable=ResTqDemand_Value
              WV_ResTqDemand_Qf: accessed-variable=ResTqDemand_Qf
              WV_StdrTqDemand_Value: accessed-variable=StdrTqDemand_Value
              WV_StdrTqDemand_Qf: accessed-variable=StdrTqDemand_Qf
              WV_PaTqDemand_Value: accessed-variable=PaTqDemand_Value
              WV_PaTqDemand_Qf: accessed-variable=PaTqDemand_Qf
              WV_AncTqDemand_Value: accessed-variable=AncTqDemand_Value
              WV_AncTqDemand_Qf: accessed-variable=AncTqDemand_Qf
              WV_PdcTqDemand_Value: accessed-variable=PdcTqDemand_Value
              WV_PdcTqDemand_Qf: accessed-variable=PdcTqDemand_Qf
              WV_AncDiagStatus: accessed-variable=AncDiagStatus
        ArbitratorSwc_arbitrateFeatures: symbol=Arbitrator_arbitrateFeatures  # Control the activation/inhibition of overlay requests and report status back to caller.
          data-read-access:
            12 x access:
              R_ACT_RET_REQ_ActivationRequest: accessed-variable=ACT_RET_REQ.ActivationRequest
              R_SYS_STATES_SystemState: accessed-variable=SYS_STATES.SystemState
              R_PDC_REQ_ActivationRequest: accessed-variable=PDC_REQ.ActivationRequest
              R_STDR_REQ_ActivationRequest: accessed-variable=STDR_REQ.ActivationRequest
              R_PDCL_REQ_ActivationRequest: accessed-variable=PDCL_REQ.ActivationRequest
              R_RES_REQ_ActivationRequest: accessed-variable=RES_REQ.ActivationRequest
              R_PA_REQ_ActivationRequest: accessed-variable=PA_REQ.ActivationRequest
              R_ANC_REQ_ActivationRequest: accessed-variable=ANC_REQ.ActivationRequest
              R_ASSIST_CAP_Capability: accessed-variable=ASSIST_CAP.Capability
              R_FIH_FN_STS_AncExecStopped: accessed-variable=FIH_FN_STS.AncExecStopped
              R_FIH_FN_STS_PdcExecStopped: accessed-variable=FIH_FN_STS.PdcExecStopped
              R_FIH_FN_STS_StdrExecStopped: accessed-variable=FIH_FN_STS.StdrExecStopped
          data-write-access:
            access W_ACT_RET_RES_ArbitrationState: accessed-variable=ACT_RET_RES.ArbitrationState
          parameter access ARB_RULEBASE: accessed-parameter=ARB_RULEBASE
          read-local-variables:
            access RV_AncDiagStatus: accessed-variable=AncDiagStatus
          written-local-variables:
            5 x access:
              WV_ActiveReturnState: accessed-variable=ActiveReturnState
              WV_PdcState: accessed-variable=PdcState
              WV_StdrState: accessed-variable=StdrState
              WV_AncState: accessed-variable=AncState
              WV_PaState: accessed-variable=PaState
        ArbitratorSwc_calculateOutputTorque: symbol=Arbitrator_calculateOutputTorque  # Add the torque demands to be applied after the assist function to the received assistance torque demand to provide the pinion torque demand.
          data-read-access:
            access R_CSC_ASSIST_DMD_AssistanceTorque: accessed-variable=CSC_ASSIST_DMD.AssistanceTorque
          data-write-access:
            access W_ASSIST_DMD_AssistanceTorque: accessed-variable=ASSIST_DMD.AssistanceTorque
            access W_IP_TRQ_DMDS_LimitingTorqueDemand: accessed-variable=IP_TRQ_DMDS.LimitingTorqueDemand
            access W_ARB_GAIN_PaBldGain: accessed-variable=ARB_GAIN.PaBldGain
          parameter access ARB_PA_MODE_IN_TIME: accessed-parameter=ARB_PA_MODE_IN_TIME
          parameter access ARB_PA_MODE_OUT_TIME: accessed-parameter=ARB_PA_MODE_OUT_TIME
          read-local-variables:
            19 x access:
              RV_ActiveReturnTqDemand_Value: accessed-variable=ActiveReturnTqDemand_Value
              RV_ActiveReturnTqDemand_Qf: accessed-variable=ActiveReturnTqDemand_Qf
              RV_DampingTqDemand_Value: accessed-variable=DampingTqDemand_Value
              RV_DampingTqDemand_Qf: accessed-variable=DampingTqDemand_Qf
              RV_HvdTqDemand_Value: accessed-variable=HvdTqDemand_Value
              RV_HvdTqDemand_Qf: accessed-variable=HvdTqDemand_Qf
              RV_ResTqDemand_Value: accessed-variable=ResTqDemand_Value
              RV_ResTqDemand_Qf: accessed-variable=ResTqDemand_Qf
              RV_PaState: accessed-variable=PaState
              RV_PaTqDemand_Value: accessed-variable=PaTqDemand_Value
              RV_PaTqDemand_Qf: accessed-variable=PaTqDemand_Qf
              RV_SrlTqDemand_Value: accessed-variable=SrlTqDemand_Value
              RV_SrlTqDemand_Qf: accessed-variable=SrlTqDemand_Qf
              RV_AncTqDemand_Value: accessed-variable=AncTqDemand_Value
              RV_AncTqDemand_Qf: accessed-variable=AncTqDemand_Qf
              RV_PdcTqDemand_Value: accessed-variable=PdcTqDemand_Value
              RV_PdcTqDemand_Qf: accessed-variable=PdcTqDemand_Qf
              RV_StdrTqDemand_Value: accessed-variable=StdrTqDemand_Value
              RV_StdrTqDemand_Qf: accessed-variable=StdrTqDemand_Qf
          sync call Call_RACK_getMaxPhysicalAssist: operation=RACK.getMaxPhysicalAssist
        ArbitratorSwc_initialiser: symbol=Arbitrator_initialiser
        ArbitratorSwc_limitSteeringReaction: symbol=Arbitrator_limitSteeringReaction
          data-read-access:
            access R_COL_DATA_ColumnTorque: accessed-variable=COL_DATA.ColumnTorque
            access R_COL_DATA_ColumnVelocity: accessed-variable=COL_DATA.ColumnVelocity
          16 x parameter access:
            ARB_SWITCH_SWS_FILT: accessed-parameter=ARB_SWITCH_SWS_FILT
            ARB_SWS_LP_FREQ: accessed-parameter=ARB_SWS_LP_FREQ
            ARB_LIMIT_VX_IN: accessed-parameter=ARB_LIMIT_VX_IN
            ARB_LIMIT_SWT_IN: accessed-parameter=ARB_LIMIT_SWT_IN
            ARB_LIMIT_SWS_OUT: accessed-parameter=ARB_LIMIT_SWS_OUT
            ARB_LIM_HYS: accessed-parameter=ARB_LIM_HYS
            ARB_LOWER_AMPLITUDE_LIMIT: accessed-parameter=ARB_LOWER_AMPLITUDE_LIMIT
            ARB_AMPLITUDE_FRACTION_OVERRUN: accessed-parameter=ARB_AMPLITUDE_FRACTION_OVERRUN
            ARB_AMPLITUDE_LIMIT_VX_IN: accessed-parameter=ARB_AMPLITUDE_LIMIT_VX_IN
            ARB_AMPLITUDE_LIMIT_TQ_OUT: accessed-parameter=ARB_AMPLITUDE_LIMIT_TQ_OUT
            ARB_FIXED_OVERRUN_RAMP_RATE: accessed-parameter=ARB_FIXED_OVERRUN_RAMP_RATE
            ARB_AMPLITUDE_FRACTION_RECOVERY: accessed-parameter=ARB_AMPLITUDE_FRACTION_RECOVERY
            ARB_OVERRUN_RAMP_RATE_OUT: accessed-parameter=ARB_OVERRUN_RAMP_RATE_OUT
            ARB_OVERRUN_RAMP_RATE_SWS_ERROR_IN: accessed-parameter=ARB_OVERRUN_RAMP_RATE_SWS_ERROR_IN
            ARB_RECOVERY_RAMP_RATE_STAGE1: accessed-parameter=ARB_RECOVERY_RAMP_RATE_STAGE1
            ARB_RECOVERY_RAMP_RATE_STAGE2: accessed-parameter=ARB_RECOVERY_RAMP_RATE_STAGE2
          read-local-variables:
            4 x access:
              RV_SrlSpdIndex: accessed-variable=SrlSpdIndex
              RV_StdrTqDemand_Value: accessed-variable=StdrTqDemand_Value
              RV_StdrTqDemand_Qf: accessed-variable=StdrTqDemand_Qf
              RV_SrlSpdFraction: accessed-variable=SrlSpdFraction
          written-local-variables:
            access WV_SrlTqDemand_Value: accessed-variable=SrlTqDemand_Value
            access WV_SrlTqDemand_Qf: accessed-variable=SrlTqDemand_Qf
        ArbitratorSwc_handleVehicleSpeedCalculations: symbol=Arbitrator_handleVehicleSpeedCalculations  # Runnable to process the vehilcle speed.
          data-read-access:
            access R_FVS_VehicleSpeed: accessed-variable=FVS.VehicleSpeed
          parameter access ARB_DEFAULT_SPEED: accessed-parameter=ARB_DEFAULT_SPEED
          written-local-variables:
            access WV_SrlSpdIndex: accessed-variable=SrlSpdIndex
            access WV_SrlSpdFraction: accessed-variable=SrlSpdFraction
  36 x constant specification:
    ArbitratorSwc_ActiveReturnState_Init: value-spec=99
    ArbitratorSwc_SrlSpdIndex_Init: value-spec=0
    ArbitratorSwc_SrlSpdFraction_Init: value-spec=0.0
    ArbitratorSwc_PdcState_Init: value-spec=99
    ArbitratorSwc_StdrState_Init: value-spec=99
    ArbitratorSwc_AncState_Init: value-spec=99
    ArbitratorSwc_PaState_Init: value-spec=99
    ArbitratorSwc_AncDiagStatus_Init: value-spec=0
    VehicleTune_ARB_PA_MODE_IN_TIME_Init: value-spec=0.5
    VehicleTune_ARB_PA_MODE_OUT_TIME_Init: value-spec=0.2
    PlatformTune_ARB_SWITCH_SWS_FILT_Init: value-spec=0
    PlatformTune_ARB_SWS_LP_FREQ_Init: value-spec=50.0
    PlatformTune_ARB_LIMIT_VX_IN_Init: value-spec=[0.0, 15.0, 40.0, 70.0, 100.0, 150.0, 200.0, 250.0]
    PlatformTune_ARB_LIMIT_SWT_IN_Init: value-spec=[-6.0, -5.0, -4.0, -2.0, 0.0, 2.0, 4.0, 5.0, 6.0]
    PlatformTune_ARB_AMPLITUDE_LIMIT_TQ_OUT_Init: value-spec=0.0
    PlatformTune_ARB_AMPLITUDE_FRACTION_OVERRUN_Init: value-spec=0.3
    PlatformTune_ARB_FIXED_OVERRUN_RAMP_RATE_Init: value-spec=8.0
    PlatformTune_ARB_OVERRUN_RAMP_RATE_SWS_ERROR_IN_Init: value-spec=[0.0, 25.0, 50.0, 100.0, 170.0, 250.0]
    PlatformTune_ARB_OVERRUN_RAMP_RATE_OUT_Init: value-spec=[0.0, 35.0, 70.0, 130.0, 300.0, 600.0]
    PlatformTune_ARB_AMPLITUDE_FRACTION_RECOVERY_Init: value-spec=0.5
    PlatformTune_ARB_RECOVERY_RAMP_RATE_STAGE1_Init: value-spec=20.0
    PlatformTune_ARB_RECOVERY_RAMP_RATE_STAGE2_Init: value-spec=40.0
    PlatformTune_ARB_LIMIT_SWS_OUT_Init: value-spec=[[-20.0, 10.0, 20.0, 30.0, 80.0, 100.0, 100.0, 100.0, 100.0], [-20.0, 10.0, 20.0, 30.0, 80.0, 100.0, 100.0, 100.0, 100.0], [-20.0, 10.0, 20.0, 20.0, 80.0, 100.0, 100.0, 100.0, 100.0], [-20.0, 10.0, 20.0, 20.0, 80.0, 100.0, 100.0, 100.0, 100.0], [-40.0, 5.0, 10.0, 15.0, 60.0, 80.0, 80.0, 80.0, 80.0], [-40.0, 0.0, 5.0, 10.0, 30.0, 40.0, 40.0, 40.0, 40.0], [-40.0, 0.0, 5.0, 10.0, 20.0, 30.0, 30.0, 30.0, 30.0], [-40.0, 0.0, 5.0, 10.0, 20.0, 30.0, 30.0, 30.0, 30.0]]
    PlatformTune_ARB_LIM_HYS_Init: value-spec=0.05
    PlatformTune_ARB_LOWER_AMPLITUDE_LIMIT_Init: value-spec=0.0
    PlatformTune_ARB_AMPLITUDE_LIMIT_VX_IN_Init: value-spec=[0.0, 15.0, 40.0, 70.0, 100.0, 150.0, 200.0, 250.0]
    PlatformTune_ARB_RULEBASE_Init: value-spec={short-label=PlatformTune_ARB_RULEBASE_Init, fields=[0, 1, 1, 1, 1, 0, 1, 1, 1, 1, 0, 1, 1, 1, 1, 0, 1, 1, 1, 1, 0, 1, 1, 1, 1, 0, 1, 1, 1, 1, 1, 1, 1, 1, 1, 0, 1, 1, 1, 1, 1, 1, 1, 1, 1, 0, 1, 1, 1, 1, 0, 1, 1, 1, 1, 1, 1, 1, 1, 1, 1, 0, 0, 0, 0, 0]}
    PlatformTune_ARB_DEFAULT_SPEED_Init: value-spec=250.0
    PlatformTune_ARB_MONITOR_ANC_ZERO_BAND_TORQUE_Init: value-spec=1.0
    PlatformTune_ARB_MONITOR_ANC_MAX_MOTOR_TORQUE_Init: value-spec=5.0
    PlatformTune_ARB_MONITOR_ANC_LOW_FREQ_TIME_TH_Init: value-spec=100
    PlatformTune_ARB_MONITOR_ANC_TORQUE_TREND_ALPHA_Init: value-spec=0.000999
    PlatformTune_ARB_MONITOR_ANC_DC_TREND_TORQUE_TH_Init: value-spec=1.0
    PlatformTune_ARB_NORMAL_ASSIST_TQ_LEVEL_Init: value-spec=100.0
    PlatformTune_ARB_LIMITER_PDC_MAX_TQ_Init: value-spec=0.0
    PlatformTune_ARB_LIMITER_PDC_STQR_Init: value-spec=1.0
package /FordPkg/FordArchitecturePkg/FordTypes
  compu method tSystemStates_Compu: 0=EPS_INITIALISATION, 1=EPS_NP_LIMITEDASSIST, 2=EPS_NP_FULLASSIST, 3=EPS_SYSF_LIMPHOME, 4=EPS_SYSF_LIMPASIDE, 5=EPS_SYSF_RAMPOUT, 6=EPS_SYSF_ASSISTOFF, 7=EPS_SHUTDOWN, 8=EPS_POWERDOWN
  8 x impl type:
    tSystemStates: category=VALUE, base-type=sint32, compu-method=tSystemStates_Compu
    tSrlVspdBkpts: category=ARRAY
      element Element: array-size=8, array-size-semantics=FIXED-SIZE, implementation-data-type=Kph
    tSrlTqBkpts: category=ARRAY
      element Element: array-size=9, array-size-semantics=FIXED-SIZE, implementation-data-type=Nm
    tSrlVBkpts: category=ARRAY
      element Element: array-size=6, array-size-semantics=FIXED-SIZE, implementation-data-type=DegreesPerSec
    tSrlTqSlewRateMap: category=ARRAY
      element Element: array-size=6, array-size-semantics=FIXED-SIZE, implementation-data-type=NmPerSec
    tSrlMap1D: category=ARRAY
      element Element: array-size=9, array-size-semantics=FIXED-SIZE, implementation-data-type=DegreesPerSec
    tSrlMap2D: category=ARRAY
      element Element: array-size=8, array-size-semantics=FIXED-SIZE, implementation-data-type=tSrlMap1D
    tArbRuleBase: category=STRUCTURE
      66 x element, all with category=TYPE_REFERENCE, implementation-data-type=Boolean:
        ANC_ALLOW_ACTIVATE_RULE_PDC
        ANC_ALLOW_ACTIVATE_RULE_PDCL
        ANC_ALLOW_ACTIVATE_RULE_STDR
        ANC_ALLOW_ACTIVATE_RULE_RES
        ANC_ALLOW_ACTIVATE_RULE_PA
        PDC_ALLOW_ACTIVATE_RULE_ANC
        PDC_ALLOW_ACTIVATE_RULE_PDCL
        PDC_ALLOW_ACTIVATE_RULE_STDR
        PDC_ALLOW_ACTIVATE_RULE_RES
        PDC_ALLOW_ACTIVATE_RULE_PA
        PDCL_ALLOW_ACTIVATE_RULE_PA
        PDCL_ALLOW_ACTIVATE_RULE_ANC
        PDCL_ALLOW_ACTIVATE_RULE_PDC
        PDCL_ALLOW_ACTIVATE_RULE_STDR
        PDCL_ALLOW_ACTIVATE_RULE_RES
        STDR_ALLOW_ACTIVATE_RULE_ANC
        STDR_ALLOW_ACTIVATE_RULE_PDC
        STDR_ALLOW_ACTIVATE_RULE_PDCL
        STDR_ALLOW_ACTIVATE_RULE_RES
        STDR_ALLOW_ACTIVATE_RULE_PA
        RES_ALLOW_ACTIVATE_RULE_ANC
        RES_ALLOW_ACTIVATE_RULE_PDC
        RES_ALLOW_ACTIVATE_RULE_PDCL
        RES_ALLOW_ACTIVATE_RULE_STDR
        RES_ALLOW_ACTIVATE_RULE_PA
        PA_ALLOW_ACTIVATE_RULE_ANC
        PA_ALLOW_ACTIVATE_RULE_PDC
        PA_ALLOW_ACTIVATE_RULE_PDCL
        PA_ALLOW_ACTIVATE_RULE_STDR
        PA_ALLOW_ACTIVATE_RULE_RES
        ANC_CONTIN_IF_ACTIVE_RULE_PDC
        ANC_CONTIN_IF_ACTIVE_RULE_PDCL
        ANC_CONTIN_IF_ACTIVE_RULE_STDR
        ANC_CONTIN_IF_ACTIVE_RULEE_RES
        ANC_CONTIN_IF_ACTIVE_RULE_PA
        PDC_CONTIN_IF_ACTIVE_RULE_ANC
        PDC_CONTIN_IF_ACTIVE_RULE_PDCL
        PDC_CONTIN_IF_ACTIVE_RULE_STDR
        PDC_CONTIN_IF_ACTIVE_RULE_RES
        PDC_CONTIN_IF_ACTIVE_RULE_EAC
        PDCL_CONTIN_IF_ACTIVE_RULE_ANC
        PDCL_CONTIN_IF_ACTIVE_RULE_PDC
        PDCL_CONTIN_IF_ACTIVE_RULE_STDR
        PDCL_CONTIN_IF_ACTIVE_RULE_RES
        PDCL_CONTIN_IF_ACTIVE_RULE_PA
        STDR_CONTIN_IF_ACTIVE_RULE_ANC
        STDR_CONTIN_IF_ACTIVE_RULE_PDC
        STDR_CONTIN_IF_ACTIVE_RULE_PDCL
        STDR_CONTIN_IF_ACTIVE_RULE_RES
        STDR_CONTIN_IF_ACTIVE_RULE_PA
        RES_CONTIN_IF_ACTIVE_RULE_ANC
        RES_CONTIN_IF_ACTIVE_RULE_PDC
        RES_CONTIN_IF_ACTIVE_RULE_PDCL
        RES_CONTIN_IF_ACTIVE_RULE_STDR
        RES_CONTIN_IF_ACTIVE_RULE_PA
        PA_CONTIN_IF_ACTIVE_RULE_ANC
        PA_CONTIN_IF_ACTIVE_RULE_PDC
        PA_CONTIN_IF_ACTIVE_RULE_PDCL
        PA_CONTIN_IF_ACTIVE_RULE_STDR
        PA_CONTIN_IF_ACTIVE_RULE_RES
        ANC_IF_LIMITED_ASSIST
        PDC_IF_LIMITED_ASSIST
        PDCL_IF_LIMITED_ASSIST
        STDR_IF_LIMITED_ASSIST
        RES_IF_LIMITED_ASSIST
        PA_IF_LIMITED_ASSIST
package /FordPkg/FordArchitecturePkg/FordTypes/ApplicationTypesPkg
  app type tSystemStates: category=VALUE, base-type=sint32, compu-method=tSystemStates_Compu
  7 x application array data type, all with category=ARRAY:
    tSrlVspdBkpts_0_0_to_300_0
      element Element: category=VALUE, type=Kph_0_0_to_300_0, array-size-semantics=FIXED-SIZE, max-number-of-elements=8
    tSrlTqBkpts_n8_0_to_8_0
      element Element: category=VALUE, type=Nm_n8_0_to_8_0, array-size-semantics=FIXED-SIZE, max-number-of-elements=9
    tSrlVBkpts_0_to_1000
      element Element: category=VALUE, type=DegreesPerSec_0_to_1000, array-size-semantics=FIXED-SIZE, max-number-of-elements=6
    tSrlTqSlewRateMap_0_to_1000
      element Element: category=VALUE, type=NmPerSec_0_to_1000, array-size-semantics=FIXED-SIZE, max-number-of-elements=6
    tSrlMap1D_n500_0_to_500_0
      element Element: category=VALUE, type=DegreesPerSec_n500_0_to_500_0, array-size-semantics=FIXED-SIZE, max-number-of-elements=9
    tSrlMap2D_n500_0_to_500_0
      element Element: category=ARRAY, type=tSrlMap1D_n500_0_to_500_0, array-size-semantics=FIXED-SIZE, max-number-of-elements=8
    tSrlMap1D
      element Element: category=VALUE, type=DegreesPerSec, array-size-semantics=FIXED-SIZE, max-number-of-elements=9
  application record data type tArbRuleBase: category=STRUCTURE
    66 x application record element, all with category=VALUE, type=Boolean_0_to_1:
      ANC_ALLOW_ACTIVATE_RULE_PDC
      ANC_ALLOW_ACTIVATE_RULE_PDCL
      ANC_ALLOW_ACTIVATE_RULE_STDR
      ANC_ALLOW_ACTIVATE_RULE_RES
      ANC_ALLOW_ACTIVATE_RULE_PA
      PDC_ALLOW_ACTIVATE_RULE_ANC
      PDC_ALLOW_ACTIVATE_RULE_PDCL
      PDC_ALLOW_ACTIVATE_RULE_STDR
      PDC_ALLOW_ACTIVATE_RULE_RES
      PDC_ALLOW_ACTIVATE_RULE_PA
      PDCL_ALLOW_ACTIVATE_RULE_PA
      PDCL_ALLOW_ACTIVATE_RULE_ANC
      PDCL_ALLOW_ACTIVATE_RULE_PDC
      PDCL_ALLOW_ACTIVATE_RULE_STDR
      PDCL_ALLOW_ACTIVATE_RULE_RES
      STDR_ALLOW_ACTIVATE_RULE_ANC
      STDR_ALLOW_ACTIVATE_RULE_PDC
      STDR_ALLOW_ACTIVATE_RULE_PDCL
      STDR_ALLOW_ACTIVATE_RULE_RES
      STDR_ALLOW_ACTIVATE_RULE_PA
      RES_ALLOW_ACTIVATE_RULE_ANC
      RES_ALLOW_ACTIVATE_RULE_PDC
      RES_ALLOW_ACTIVATE_RULE_PDCL
      RES_ALLOW_ACTIVATE_RULE_STDR
      RES_ALLOW_ACTIVATE_RULE_PA
      PA_ALLOW_ACTIVATE_RULE_ANC
      PA_ALLOW_ACTIVATE_RULE_PDC
      PA_ALLOW_ACTIVATE_RULE_PDCL
      PA_ALLOW_ACTIVATE_RULE_STDR
      PA_ALLOW_ACTIVATE_RULE_RES
      ANC_CONTIN_IF_ACTIVE_RULE_PDC
      ANC_CONTIN_IF_ACTIVE_RULE_PDCL
      ANC_CONTIN_IF_ACTIVE_RULE_STDR
      ANC_CONTIN_IF_ACTIVE_RULEE_RES
      ANC_CONTIN_IF_ACTIVE_RULE_PA
      PDC_CONTIN_IF_ACTIVE_RULE_ANC
      PDC_CONTIN_IF_ACTIVE_RULE_PDCL
      PDC_CONTIN_IF_ACTIVE_RULE_STDR
      PDC_CONTIN_IF_ACTIVE_RULE_RES
      PDC_CONTIN_IF_ACTIVE_RULE_EAC
      PDCL_CONTIN_IF_ACTIVE_RULE_ANC
      PDCL_CONTIN_IF_ACTIVE_RULE_PDC
      PDCL_CONTIN_IF_ACTIVE_RULE_STDR
      PDCL_CONTIN_IF_ACTIVE_RULE_RES
      PDCL_CONTIN_IF_ACTIVE_RULE_PA
      STDR_CONTIN_IF_ACTIVE_RULE_ANC
      STDR_CONTIN_IF_ACTIVE_RULE_PDC
      STDR_CONTIN_IF_ACTIVE_RULE_PDCL
      STDR_CONTIN_IF_ACTIVE_RULE_RES
      STDR_CONTIN_IF_ACTIVE_RULE_PA
      RES_CONTIN_IF_ACTIVE_RULE_ANC
      RES_CONTIN_IF_ACTIVE_RULE_PDC
      RES_CONTIN_IF_ACTIVE_RULE_PDCL
      RES_CONTIN_IF_ACTIVE_RULE_STDR
      RES_CONTIN_IF_ACTIVE_RULE_PA
      PA_CONTIN_IF_ACTIVE_RULE_ANC
      PA_CONTIN_IF_ACTIVE_RULE_PDC
      PA_CONTIN_IF_ACTIVE_RULE_PDCL
      PA_CONTIN_IF_ACTIVE_RULE_STDR
      PA_CONTIN_IF_ACTIVE_RULE_RES
      ANC_IF_LIMITED_ASSIST
      PDC_IF_LIMITED_ASSIST
      PDCL_IF_LIMITED_ASSIST
      STDR_IF_LIMITED_ASSIST
      RES_IF_LIMITED_ASSIST
      PA_IF_LIMITED_ASSIST
